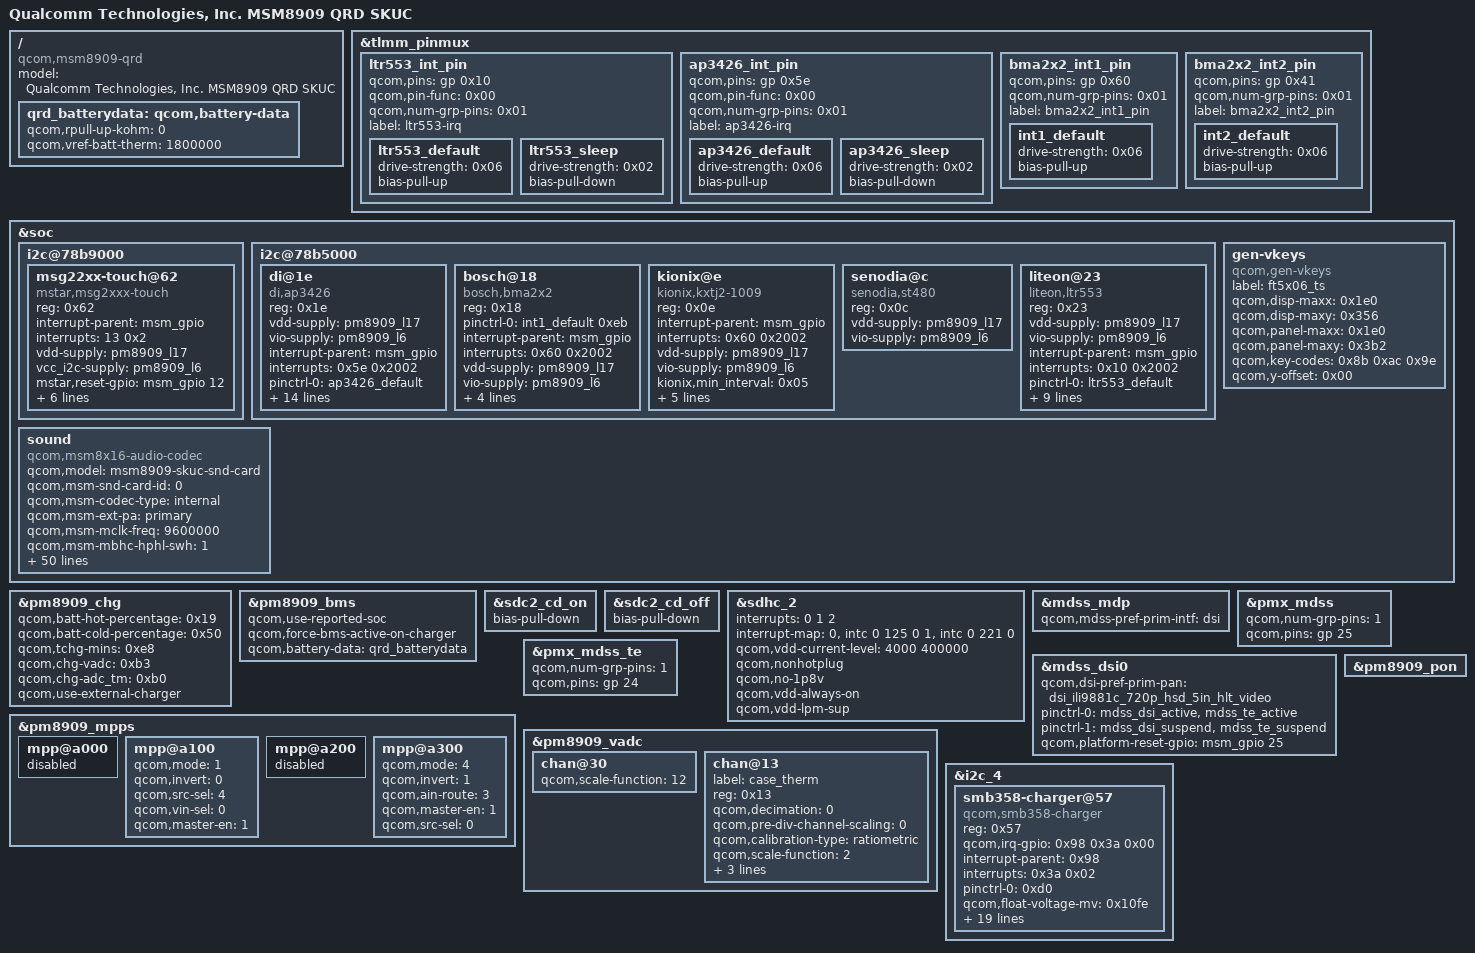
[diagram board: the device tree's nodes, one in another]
/* Copyright (c) 2014-2015, The Linux Foundation. All rights reserved.
 *
 * This program is free software; you can redistribute it and/or modify
 * it under the terms of the GNU General Public License version 2 and
 * only version 2 as published by the Free Software Foundation.
 *
 * This program is distributed in the hope that it will be useful,
 * but WITHOUT ANY WARRANTY; without even the implied warranty of
 * MERCHANTABILITY or FITNESS FOR A PARTICULAR PURPOSE.  See the
 * GNU General Public License for more details.
 */

#include "msm8909-camera-sensor-b26d2h.dtsi"
#include "dsi-panel-ili9806e_fwvga_hsd_hlt-video.dtsi"
#include "dsi-panel-ili9806e_fwvga_hsd_huashi-video.dtsi"
#include "dsi-panel-ili9881c_720p_hsd_5in_hlt-video.dtsi"

/ {
	model = "Qualcomm Technologies, Inc. MSM8909 QRD SKUC";
	compatible = "qcom,msm8909-qrd", "qcom,msm8909", "qcom,qrd";
};

&tlmm_pinmux {
	ltr553_int_pin {
		qcom,pins = <&gp 0x10>;
		qcom,pin-func = < 0x00 >;
		qcom,num-grp-pins = < 0x01 >;
		label = "ltr553-irq";

		ltr553_default: ltr553_default {
			drive-strength = < 0x06 >;
			bias-pull-up;
		};

		ltr553_sleep: ltr553_sleep {
			drive-strength = < 0x02 >;
			bias-pull-down;
		};
	};

	ap3426_int_pin {
		qcom,pins = <&gp 0x5e>;
		qcom,pin-func = < 0x00 >;
		qcom,num-grp-pins = < 0x01 >;
		label = "ap3426-irq";

		ap3426_default: ap3426_default {
			drive-strength = < 0x06 >;
			bias-pull-up;
		};

		ap3426_sleep: ap3426_sleep {
			drive-strength = < 0x02 >;
			bias-pull-down;
		};
	};

	bma2x2_int1_pin {
		qcom,pins = <&gp 0x60>;
		qcom,num-grp-pins = < 0x01 >;
		label = "bma2x2_int1_pin";

		int1_default: int1_default {
			drive-strength = < 0x06 >;
			bias-pull-up;
		};
	};

	bma2x2_int2_pin {
		qcom,pins = <&gp 0x41 >;
		qcom,num-grp-pins = < 0x01 >;
		label = "bma2x2_int2_pin";

		int2_default: int2_default {
			drive-strength = < 0x06 >;
			bias-pull-up;
		};
	};
};

&soc {
	i2c@78b9000 { /* BLSP1 QUP5 */
		msg22xx-touch@62 {
			compatible = "mstar,msg2xxx-touch";
			reg = <0x62>;
			interrupt-parent = <&msm_gpio>;
			interrupts = <13 0x2>;
			vdd-supply = <&pm8909_l17>;
			vcc_i2c-supply = <&pm8909_l6>;
			mstar,reset-gpio = <&msm_gpio 12 0x00>;
			mstar,irq-gpio = <&msm_gpio 13 0x00>;
			pinctrl-names = "pmx_ts_active","pmx_ts_suspend", "pmx_ts_release";
			pinctrl-0 = <&ts_int_active &ts_reset_active &ts_int_active>;
			pinctrl-1 = <&ts_int_suspend &ts_reset_suspend &ts_int_active>;
			pinctrl-2 = <&ts_release>;
		};
	};

	i2c@78b5000 { /* BLSP1 QUP1 */
		di@1e {
			compatible = "di,ap3426";
			reg = < 0x1e >;
			vdd-supply = <&pm8909_l17>;
			vio-supply = <&pm8909_l6>;
			interrupt-parent = <&msm_gpio>;
			interrupts = <0x5e 0x2002>;
			pinctrl-names = "default","sleep";
			pinctrl-0 = <&ap3426_default>;
			pinctrl-1 = <&ap3426_sleep>;
			di,irq-gpio = <&msm_gpio 0x5e 0x2002 >;
			di,als-cal = < 0x5e >;
			di,als-gain = < 0x00 >;
			di,als-persist = < 0x01 >;
			di,ps-gain = < 0x01 >;
			di,ps-persist = < 0x02 >;
			di,ps-led-driver = < 0x03 >;
			di,ps-mean-time = < 0x00 >;
			di,ps-integrated-time = < 0x00 >;
			di,ps-distance-table = < 0x377 0x11a 0x6f 0x4e 0x35 0x2e >;
			di,als-sensitivity = < 0x32 >;
			di,wakeup-threshold = < 0x04 >;
		};

		bosch@18 {
			compatible = "bosch,bma2x2";
			reg = <0x18>;
			pinctrl-names = "default";
			pinctrl-0 = <&int1_default 0xeb>;
			interrupt-parent = <&msm_gpio>;
			interrupts = <0x60 0x2002>;
			vdd-supply = <&pm8909_l17>;
			vio-supply = <&pm8909_l6>;
			bosch,init-interval = < 0xc8 >;
			bosch,place = < 0x05 >;
			bosch,gpio-int1 = <&msm_gpio 0x60 0x2002 >;
			bosch,gpio-int2 = <&msm_gpio 0x41 0x2002 >;
		};

		kionix@e {
			compatible = "kionix,kxtj2-1009";
			reg = < 0x0e >;
			interrupt-parent = <&msm_gpio>;
			interrupts = <0x60 0x2002>;
			vdd-supply = <&pm8909_l17>;
			vio-supply = <&pm8909_l6>;
			kionix,min_interval = < 0x05 >;
			kionix,poll_interval = < 0x64 >;
			kionix,accel_direction = < 0x01 >;
			kionix,accel_irq_use_drdy = < 0x00 >;
			kionix,accel_res = < 0x0c >;
			kionix,accel_g_range = < 0x02 >;
		};

		senodia@c {
			compatible = "senodia,st480";
			reg = < 0x0c >;
			vdd-supply = <&pm8909_l17>;
			vio-supply = <&pm8909_l6>;
		};

		liteon@23 {
			compatible = "liteon,ltr553";
			reg = < 0x23 >;
			vdd-supply = <&pm8909_l17>;
			vio-supply = <&pm8909_l6>;
			interrupt-parent = <&msm_gpio>;
			interrupts = <0x10 0x2002>;
			pinctrl-names = "default","sleep";
			pinctrl-0 = <&ltr553_default>;
			pinctrl-1 = <&ltr553_sleep>;
			liteon,irq-gpio = <&msm_gpio 0x10 0x2002>;
			liteon,als-ps-persist = < 0x00 >;
			liteon,ps-led = < 0x7f >;
			liteon,ps-pulses = < 0x04 >;
			liteon,wakeup-threshold = < 0x04 >;
			liteon,als-integration-time = < 0x00 >;
			liteon,ps-distance-table = < 0x560 0x236 0x157 0x11f 0xc8 0xaa 0x9b >;
		};
	};

	gen-vkeys {
		compatible = "qcom,gen-vkeys";
		label = "ft5x06_ts";
		qcom,disp-maxx = < 0x1e0 >;
		qcom,disp-maxy = < 0x356 >;
		qcom,panel-maxx = < 0x1e0 >;
		qcom,panel-maxy = < 0x3b2 >;
		qcom,key-codes = < 0x8b 0xac 0x9e >;
		qcom,y-offset = < 0x00 >;
	};

	sound {
		compatible = "qcom,msm8x16-audio-codec";
		qcom,model = "msm8909-skuc-snd-card";
		qcom,msm-snd-card-id = <0>;
		qcom,msm-codec-type = "internal";
		qcom,msm-ext-pa = "primary";
		qcom,msm-mclk-freq = <9600000>;
		qcom,msm-mbhc-hphl-swh = <1>;
		qcom,msm-mbhc-gnd-swh = <0>;
		qcom,msm-hs-micbias-type = "internal";
		qcom,msm-spk-ext-pa = <&msm_gpio 0x03 0x00>;
		qcom,msm-micbias1-ext-cap;
		qcom,msm-micbias2-ext-cap;
		qcom,audio-routing =
			"RX_BIAS", "MCLK",
			"SPK_RX_BIAS", "MCLK",
			"INT_LDO_H", "MCLK",
			"MIC BIAS Internal1", "Handset Mic",
			"MIC BIAS Internal2", "Headset Mic",
			"MIC BIAS Internal3", "Secondary Mic",
			"AMIC1", "MIC BIAS Internal1",
			"AMIC2", "MIC BIAS Internal2",
			"AMIC3", "MIC BIAS Internal3";
		pinctrl-names = "cdc_lines_act",
				"cdc_lines_sus";
		pinctrl-0 = <&cdc_pdm_lines_act>;
		pinctrl-1 = <&cdc_pdm_lines_sus>;
		asoc-platform = <&pcm0>, <&pcm1>, <&voip>, <&voice>,
				<&loopback>, <&compress>, <&hostless>,
				<&afe>, <&lsm>, <&routing>, <&lpa>,
				<&voice_svc>;
		asoc-platform-names = "msm-pcm-dsp.0", "msm-pcm-dsp.1",
				"msm-voip-dsp", "msm-pcm-voice", "msm-pcm-loopback",
				"msm-compress-dsp", "msm-pcm-hostless", "msm-pcm-afe",
				"msm-lsm-client", "msm-pcm-routing", "msm-pcm-lpa",
				"msm-voice-svc";
		asoc-cpu = <&dai_pri_auxpcm>, <&dai_hdmi>,
				<&dai_mi2s0>, <&dai_mi2s1>, <&dai_mi2s2>, <&dai_mi2s3>,
				<&sb_0_rx>, <&sb_0_tx>, <&sb_1_rx>, <&sb_1_tx>,
				<&sb_3_rx>, <&sb_3_tx>, <&sb_4_rx>, <&sb_4_tx>,
				<&bt_sco_rx>, <&bt_sco_tx>, <&bt_a2dp_rx>,
				<&int_fm_rx>, <&int_fm_tx>,
				<&afe_pcm_rx>, <&afe_pcm_tx>, <&afe_proxy_rx>, <&afe_proxy_tx>,
				<&incall_record_rx>, <&incall_record_tx>, <&incall_music_rx>,
				<&incall_music_2_rx>;
		asoc-cpu-names = "msm-dai-q6-auxpcm.1", "msm-dai-q6-hdmi.8",
				"msm-dai-q6-mi2s.0", "msm-dai-q6-mi2s.1",
				"msm-dai-q6-mi2s.2", "msm-dai-q6-mi2s.3",
				"msm-dai-q6-dev.16384", "msm-dai-q6-dev.16385",
				"msm-dai-q6-dev.16386", "msm-dai-q6-dev.16387",
				"msm-dai-q6-dev.16390", "msm-dai-q6-dev.16391",
				"msm-dai-q6-dev.16392", "msm-dai-q6-dev.16393",
				"msm-dai-q6-dev.12288", "msm-dai-q6-dev.12289",
				"msm-dai-q6-dev.12290", "msm-dai-q6-dev.12292",
				"msm-dai-q6-dev.12293",	"msm-dai-q6-dev.224",
				"msm-dai-q6-dev.225", "msm-dai-q6-dev.241",
				"msm-dai-q6-dev.240", "msm-dai-q6-dev.32771",
				"msm-dai-q6-dev.32772", "msm-dai-q6-dev.32773",
				"msm-dai-q6-dev.32770";
		asoc-codec = <&stub_codec>, <&pm8909_conga_dig>;
		asoc-codec-names = "msm-stub-codec.1", "tombak_codec";
	};
};

&pm8909_chg {
	qcom,batt-hot-percentage = < 0x19 >;
	qcom,batt-cold-percentage = < 0x50 >;
	qcom,tchg-mins = < 0xe8 >;
	qcom,chg-vadc = < 0xb3 >;
	qcom,chg-adc_tm = < 0xb0 >;
	status = "ok";
	qcom,use-external-charger;
};

/ {
	qrd_batterydata: qcom,battery-data {
		qcom,rpull-up-kohm = <0>;
		qcom,vref-batt-therm = <1800000>;

		#include "batterydata-veken-4v35-2400mah.dtsi"
	};
};

&pm8909_bms {
	status = "okay";
	qcom,use-reported-soc;
	qcom,force-bms-active-on-charger;
	qcom,battery-data = <&qrd_batterydata>;
};

&sdc2_cd_on {
	/delete-property/ bias-pull-up;
	bias-pull-down;
};

&sdc2_cd_off {
	/delete-property/ bias-disable;
	bias-pull-down;
};

&sdhc_2 {
	interrupts = <0 1 2>;
	interrupt-map = <0 &intc 0 125 0
		1 &intc 0 221 0>;
	interrupt-names = "hc_irq", "pwr_irq";
	qcom,vdd-current-level = <4000 400000>;
	/delete-property/ cd-gpios;
	qcom,nonhotplug;
	qcom,no-1p8v;
	qcom,vdd-always-on;
	qcom,vdd-lpm-sup;
};

&pm8909_mpps {
	mpp@a000 { /* MPP 1 */
		/* VDD_PX */
		status = "disabled";
	};

	mpp@a100 { /* MPP 2 */
		/* Backlight PWM */
		qcom,mode = <1>;		/* Digital output */
		qcom,invert = <0>;		/* Disable invert */
		qcom,src-sel = <4>;		/* DTEST1 */
		qcom,vin-sel = <0>;		/* VPH_PWR */
		qcom,master-en = <1>;		/* Enable MPP */
	};

	mpp@a200 { /* MPP 3 */
		/* VREF DAC */
		status = "disabled";
	};

	mpp@a300 { /* MPP 4 */
		 /* PA_THERM config */
		 qcom,mode = <4>; /* AIN input */
		 qcom,invert = <1>; /* Enable MPP */
		 qcom,ain-route = <3>; /* AMUX 8 */
		 qcom,master-en = <1>;
		 qcom,src-sel = <0>; /* Function constant */
	};
};

&mdss_mdp {
	qcom,mdss-pref-prim-intf = "dsi";
};

&pmx_mdss {
	qcom,num-grp-pins = <1>;
	qcom,pins = <&gp 25>;
};

&pmx_mdss_te {
	qcom,num-grp-pins = <1>;
	qcom,pins = <&gp 24>;
};

&mdss_dsi0 {
	qcom,dsi-pref-prim-pan = <&dsi_ili9881c_720p_hsd_5in_hlt_video>;
	pinctrl-names = "mdss_default", "mdss_sleep";
	pinctrl-0 = <&mdss_dsi_active &mdss_te_active>;
	pinctrl-1 = <&mdss_dsi_suspend &mdss_te_suspend>;

	qcom,platform-reset-gpio = <&msm_gpio 25 0>;
};

&pm8909_vadc {
	chan@30 {
		qcom,scale-function = <12>;
	};

	chan@13 {
		label = "case_therm";
		reg = <0x13>;
		qcom,decimation = <0>;
		qcom,pre-div-channel-scaling = <0>;
		qcom,calibration-type = "ratiometric";
		qcom,scale-function = <2>;
		qcom,hw-settle-time = <2>;
		qcom,fast-avg-setup = <0>;
		qcom,vadc-thermal-node;
	};
};

&i2c_4 {
	smb358-charger@57 {
		compatible = "qcom,smb358-charger";
		reg = < 0x57 >;
		qcom,irq-gpio = < 0x98 0x3a 0x00 >;
		interrupt-parent = < 0x98 >;
		interrupts = < 0x3a 0x02 >;
		pinctrl-names = "default";
		pinctrl-0 = < 0xd0 >;
		qcom,float-voltage-mv = < 0x10fe >;
		qcom,chg-inhibit-disabled;
		qcom,fastchg-current-max-ma = < 0x5dc >;
		qcom,bms-psy-name = "bms";
		qcom,chg-vadc = < 0xb3 >;
		qcom,chg-adc_tm = < 0xb0 >;
		qcom,iterm-ma = < 0x64 >;
		qcom,recharge-mv = < 0x64 >;
		regulator-name = "smb358_otg_vreg";
		qcom,using-pmic-therm;
		qcom,bms-controlled-charging;
		qcom,bat-present-decidegc = < 0xc8 >;
		qcom,hot-bat-decidegc = < 0x226 >;
		qcom,warm-bat-decidegc = < 0x1c2 >;
		qcom,cool-bat-decidegc = < 0x64 >;
		qcom,cold-bat-decidegc = < 0x00 >;
		qcom,warm-bat-ma = < 0x1f4 >;
		qcom,cool-bat-ma = < 0x1f4 >;
		qcom,warm-bat-mv = < 0x1068 >;
		qcom,cool-bat-mv = < 0x1068 >;
	};
};

&pm8909_pon{
	/delete-property/ qcom,store-hard-reset-reason;
};
